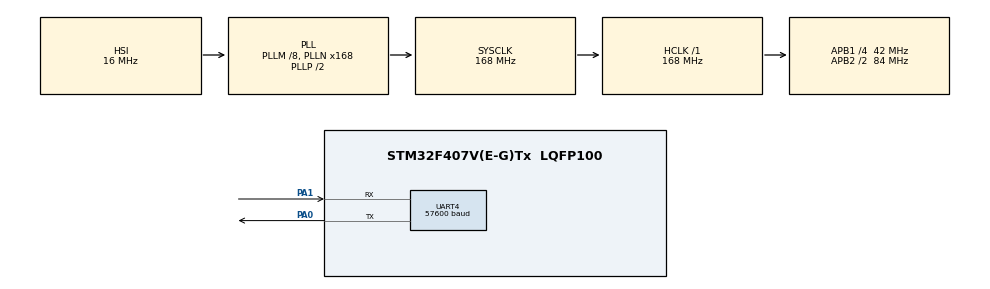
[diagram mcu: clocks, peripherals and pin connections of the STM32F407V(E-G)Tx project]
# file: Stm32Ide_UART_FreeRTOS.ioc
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FREERTOS.Tasks01=defaultTask,24,128,StartDefaultTask,Default,NULL,Dynamic,NULL,NULL
Mcu.Family=STM32F4
Mcu.Name=STM32F407V(E-G)Tx
Mcu.Package=LQFP100
NVIC.PriorityGroup=NVIC_PRIORITYGROUP_4
NVIC.TIM1_UP_TIM10_IRQn=true\:0\:0\:false\:false\:true\:false\:false\:true
NVIC.TimeBase=TIM1_UP_TIM10_IRQn
NVIC.TimeBaseIP=TIM1
PA0-WKUP.Mode=Asynchronous
PA0-WKUP.Signal=UART4_TX
PA1.Mode=Asynchronous
PA1.Signal=UART4_RX
PA13.Mode=Serial_Wire
PA13.Signal=SYS_JTMS-SWDIO
PA14.Mode=Serial_Wire
PA14.Signal=SYS_JTCK-SWCLK
ProjectManager.HeapSize=0x200
ProjectManager.StackSize=0x400
ProjectManager.TargetToolchain=STM32CubeIDE
RCC.48MHZClocksFreq_Value=84000000
RCC.AHBFreq_Value=168000000
RCC.APB1CLKDivider=RCC_HCLK_DIV4
RCC.APB1Freq_Value=42000000
RCC.APB1TimFreq_Value=84000000
RCC.APB2CLKDivider=RCC_HCLK_DIV2
RCC.APB2Freq_Value=84000000
RCC.APB2TimFreq_Value=168000000
RCC.CortexFreq_Value=168000000
RCC.HCLKFreq_Value=168000000
RCC.HSE_VALUE=25000000
RCC.HSI_VALUE=16000000
RCC.LSE_VALUE=32768
RCC.PLLM=8
RCC.PLLN=168
RCC.SYSCLKFreq_VALUE=168000000
RCC.SYSCLKSource=RCC_SYSCLKSOURCE_PLLCLK
RCC.VCOOutputFreq_Value=336000000
UART4.BaudRate=57600
UART4.VirtualMode=Asynchronous
VP_FREERTOS_VS_CMSIS_V2.Mode=CMSIS_V2
VP_SYS_VS_tim1.Mode=TIM1
board=custom

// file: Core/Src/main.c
/* USER CODE BEGIN Header */
/**
  ******************************************************************************
  * @file           : main.c
  * @brief          : Main program body
  ******************************************************************************
  * @attention
  *
  * <h2><center>&copy; Copyright (c) 2021 STMicroelectronics.
  * All rights reserved.</center></h2>
  *
  * This software component is licensed by ST under BSD 3-Clause license,
  * the "License"; You may not use this file except in compliance with the
  * License. You may obtain a copy of the License at:
  *                        opensource.org/licenses/BSD-3-Clause
  *
  ******************************************************************************
  */
/* USER CODE END Header */
#include "main.h"
#include "cmsis_os.h"

UART_HandleTypeDef huart4;

/* Definitions for defaultTask */
osThreadId_t defaultTaskHandle;
const osThreadAttr_t defaultTask_attributes = {
  .name = "defaultTask",
  .priority = (osPriority_t) osPriorityNormal,
  .stack_size = 128 * 4
};
/* USER CODE BEGIN PV */
//FIRST COMMENT
/* USER CODE END PV */

void SystemClock_Config(void);
static void MX_GPIO_Init(void);
static void MX_UART4_Init(void);
void StartDefaultTask(void *argument);

int main(void)
{

  /* MCU Configuration--------------------------------------------------------*/

  /* Reset of all peripherals, Initializes the Flash interface and the Systick. */
  HAL_Init();

  /* Configure the system clock */
  SystemClock_Config();

  /* Initialize all configured peripherals */
  MX_GPIO_Init();
  MX_UART4_Init();

  /* Init scheduler */
  osKernelInitialize();

  /* Create the thread(s) */
  /* creation of defaultTask */
  defaultTaskHandle = osThreadNew(StartDefaultTask, NULL, &defaultTask_attributes);

  /* Start scheduler */
  osKernelStart();

  /* We should never get here as control is now taken by the scheduler */
  /* Infinite loop */
  while (1)
  {

  }
}

void SystemClock_Config(void)
{
  RCC_OscInitTypeDef RCC_OscInitStruct = {0};
  RCC_ClkInitTypeDef RCC_ClkInitStruct = {0};

  /** Configure the main internal regulator output voltage
  */
  __HAL_RCC_PWR_CLK_ENABLE();
  __HAL_PWR_VOLTAGESCALING_CONFIG(PWR_REGULATOR_VOLTAGE_SCALE1);
  /** Initializes the RCC Oscillators according to the specified parameters
  * in the RCC_OscInitTypeDef structure.
  */
  RCC_OscInitStruct.OscillatorType = RCC_OSCILLATORTYPE_HSI;
  RCC_OscInitStruct.HSIState = RCC_HSI_ON;
  RCC_OscInitStruct.HSICalibrationValue = RCC_HSICALIBRATION_DEFAULT;
  RCC_OscInitStruct.PLL.PLLState = RCC_PLL_ON;
  RCC_OscInitStruct.PLL.PLLSource = RCC_PLLSOURCE_HSI;
  RCC_OscInitStruct.PLL.PLLM = 8;
  RCC_OscInitStruct.PLL.PLLN = 168;
  RCC_OscInitStruct.PLL.PLLP = RCC_PLLP_DIV2;
  RCC_OscInitStruct.PLL.PLLQ = 4;
  if (HAL_RCC_OscConfig(&RCC_OscInitStruct) != HAL_OK)
  {
    Error_Handler();
  }
  /** Initializes the CPU, AHB and APB buses clocks
  */
  RCC_ClkInitStruct.ClockType = RCC_CLOCKTYPE_HCLK|RCC_CLOCKTYPE_SYSCLK
                              |RCC_CLOCKTYPE_PCLK1|RCC_CLOCKTYPE_PCLK2;
  RCC_ClkInitStruct.SYSCLKSource = RCC_SYSCLKSOURCE_PLLCLK;
  RCC_ClkInitStruct.AHBCLKDivider = RCC_SYSCLK_DIV1;
  RCC_ClkInitStruct.APB1CLKDivider = RCC_HCLK_DIV4;
  RCC_ClkInitStruct.APB2CLKDivider = RCC_HCLK_DIV2;

  if (HAL_RCC_ClockConfig(&RCC_ClkInitStruct, FLASH_LATENCY_5) != HAL_OK)
  {
    Error_Handler();
  }
}

static void MX_UART4_Init(void)
{

  huart4.Instance = UART4;
  huart4.Init.BaudRate = 57600;
  huart4.Init.WordLength = UART_WORDLENGTH_8B;
  huart4.Init.StopBits = UART_STOPBITS_1;
  huart4.Init.Parity = UART_PARITY_NONE;
  huart4.Init.Mode = UART_MODE_TX_RX;
  huart4.Init.HwFlowCtl = UART_HWCONTROL_NONE;
  huart4.Init.OverSampling = UART_OVERSAMPLING_16;
  if (HAL_UART_Init(&huart4) != HAL_OK)
  {
    Error_Handler();
  }

}

static void MX_GPIO_Init(void)
{

  /* GPIO Ports Clock Enable */
  __HAL_RCC_GPIOA_CLK_ENABLE();

}

void StartDefaultTask(void *argument)
{
  for(;;)
  {
    osDelay(1);
  }
}

 /**
  * @brief  Period elapsed callback in non blocking mode
  * @note   This function is called  when TIM1 interrupt took place, inside
  * HAL_TIM_IRQHandler(). It makes a direct call to HAL_IncTick() to increment
  * a global variable "uwTick" used as application time base.
  * @param  htim : TIM handle
  * @retval None
  */
void HAL_TIM_PeriodElapsedCallback(TIM_HandleTypeDef *htim)
{
  if (htim->Instance == TIM1) {
    HAL_IncTick();
  }
}

void Error_Handler(void)
{
  __disable_irq();
  while (1)
  {
  }
}

/************************ (C) COPYRIGHT STMicroelectronics *****END OF FILE****/
